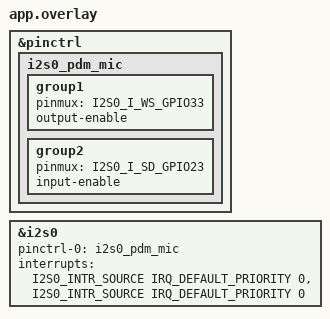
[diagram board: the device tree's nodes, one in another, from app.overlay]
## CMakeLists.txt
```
# Copyright (c) 2026 Eoin Jordan
# SPDX-License-Identifier: Apache-2.0
#
# "Hey Zephyr" wake word on the M5Stack ATOM Echo (ESP32-PICO-D4) under Zephyr.
# Same structure as the upstream zephyr/samples/hello-executorch sample: the
# model is embedded as a const array and only the operators it uses are linked.

cmake_minimum_required(VERSION 3.24)

set(CMAKE_SKIP_INSTALL_RULES ON CACHE BOOL "" FORCE)

set(ET_PTE_FILE_PATH
    "${CMAKE_CURRENT_SOURCE_DIR}/model/kws.pte"
    CACHE FILEPATH "Path to the ExecuTorch .pte model to embed"
)
if(NOT IS_ABSOLUTE "${ET_PTE_FILE_PATH}")
  get_filename_component(
    ET_PTE_FILE_PATH "${ET_PTE_FILE_PATH}" ABSOLUTE BASE_DIR
    "${CMAKE_CURRENT_SOURCE_DIR}"
  )
endif()
if(NOT EXISTS "${ET_PTE_FILE_PATH}")
  message(FATAL_ERROR "Model not found at ET_PTE_FILE_PATH=${ET_PTE_FILE_PATH}. "
                      "Run train/export_kws.py first or pass -DET_PTE_FILE_PATH=<file>.")
endif()

find_package(Zephyr REQUIRED HINTS $ENV{ZEPHYR_BASE})
project(atom_echo_hey_zephyr)

find_package(Python3 COMPONENTS Interpreter REQUIRED)

set(CMAKE_CXX_FLAGS
    "${CMAKE_CXX_FLAGS} -Wall -Wno-switch -Wno-float-conversion -ffunction-sections -fdata-sections"
)

if(NOT DEFINED EXECUTORCH_DIR)
  if(DEFINED ZEPHYR_EXECUTORCH_MODULE_DIR)
    set(EXECUTORCH_DIR ${ZEPHYR_EXECUTORCH_MODULE_DIR})
  else()
    message(FATAL_ERROR "ExecuTorch Zephyr module not found. Check west.yml and run west update.")
  endif()
endif()
message(STATUS "EXECUTORCH_DIR=${EXECUTORCH_DIR}")

include(${EXECUTORCH_DIR}/tools/cmake/Utils.cmake)
include(${EXECUTORCH_DIR}/backends/arm/cmake/ArmRunnerUtils.cmake)

if(NOT TARGET portable_kernels)
  set(EXECUTORCH_PORTABLE_BUILD_KERNELS_ONLY ON)
  add_subdirectory(
    ${EXECUTORCH_DIR}/kernels/portable
    ${CMAKE_CURRENT_BINARY_DIR}/executorch/kernels/portable
  )
  unset(EXECUTORCH_PORTABLE_BUILD_KERNELS_ONLY)
endif()

arm_runner_create_selected_ops_lib(
  LIB_NAME "kws_portable_ops_lib"
  FUNCTIONS_YAML "${EXECUTORCH_DIR}/kernels/portable/functions.yaml"
  OPS_FROM_MODEL "${ET_PTE_FILE_PATH}"
  KERNEL_LIBS portable_kernels
  DEPS executorch
  DTYPE_SELECTIVE_BUILD ""
)

set(_local_flatcc_root ${CMAKE_BINARY_DIR}/flatcc_src)
if(NOT EXISTS ${_local_flatcc_root}/CMakeLists.txt)
  file(MAKE_DIRECTORY ${_local_flatcc_root})
  execute_process(
    COMMAND ${CMAKE_COMMAND} -E copy_directory
            ${EXECUTORCH_DIR}/third-party/flatcc ${_local_flatcc_root}
  )
endif()
set(EXECUTORCH_FLATCC_SOURCE_ROOT ${_local_flatcc_root} CACHE PATH "" FORCE)
set(EXECUTORCH_FLATCC_INSTALL_ROOT ${_local_flatcc_root} CACHE PATH "" FORCE)

set(_model_pte_header ${CMAKE_CURRENT_BINARY_DIR}/model_pte.h)
add_custom_command(
  OUTPUT ${_model_pte_header}
  COMMAND ${Python3_EXECUTABLE} ${CMAKE_CURRENT_SOURCE_DIR}/scripts/pte_to_header.py
          --pte ${ET_PTE_FILE_PATH} --out ${_model_pte_header}
  DEPENDS ${ET_PTE_FILE_PATH} ${CMAKE_CURRENT_SOURCE_DIR}/scripts/pte_to_header.py
  COMMENT "Converting ${ET_PTE_FILE_PATH} to model_pte.h"
)
add_custom_target(gen_model_header DEPENDS ${_model_pte_header})
add_dependencies(app gen_model_header)

# The ExecuTorch module's runtime includes <zephyr/kernel.h>, which needs
# Zephyr's generated headers. Order it explicitly so a parallel build does not
# compile it before they exist.
if(TARGET zephyr_generated_headers)
  foreach(_t executorch_core executorch portable_kernels kernels_util_all_deps)
    if(TARGET ${_t})
      add_dependencies(${_t} zephyr_generated_headers)
    endif()
  endforeach()
endif()

target_sources(app PRIVATE src/main.cpp src/mic.c src/mfcc.c src/led.c)

target_compile_definitions(
  app PRIVATE
  APP_METHOD_ALLOCATOR_POOL_SIZE=${CONFIG_EXECUTORCH_METHOD_ALLOCATOR_POOL_SIZE}
  APP_TEMP_ALLOCATOR_POOL_SIZE=${CONFIG_EXECUTORCH_TEMP_ALLOCATOR_POOL_SIZE}
  MIC_RING_SAMPLES=16384
)

target_link_libraries(app PRIVATE libexecutorch kws_portable_ops_lib)
target_include_directories(app PRIVATE src ${CMAKE_CURRENT_BINARY_DIR})
```

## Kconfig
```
# Copyright (c) 2026 Eoin Jordan
# SPDX-License-Identifier: Apache-2.0

mainmenu "Hey Zephyr wake word on the M5Stack ATOM Echo"

config EXECUTORCH_METHOD_ALLOCATOR_POOL_SIZE
	int "ExecuTorch method allocator pool (bytes)"
	default 32768

config EXECUTORCH_TEMP_ALLOCATOR_POOL_SIZE
	int "ExecuTorch temp allocator pool (bytes)"
	default 8192

config APP_INFER_PERIOD_MS
	int "How often the newest second of audio is scored (ms)"
	default 250

config APP_WAKE_THRESHOLD_PERCENT
	int "p(hey_zephyr) that counts as a hit (percent)"
	default 85

config APP_WAKE_CONSECUTIVE
	int "Consecutive hits needed before a wake event"
	default 2

config APP_WAKE_HOLDOFF_MS
	int "Ignore further hits for this long after a wake event (ms)"
	default 1500

config APP_HEARTBEAT_MS
	int "Heartbeat JSON line period (ms)"
	default 5000

config APP_MIC_I2S_FRAME_HZ
	int "I2S frame clock the driver is configured for (Hz)"
	default 32000
	help
	  With 16-bit stereo frames the bit clock is 32 x this. 32000 gives the
	  1.024 MHz PDM clock that yields 16 kHz PCM from the ESP32's PDM-to-PCM
	  filter at DSR 8.

config APP_MIC_PICK
	int "Which halfword of each DMA word is the sample (-1 = measure and pick)"
	default -1
	range -1 2

choice APP_MIC_SLOT
	prompt "PDM slot the microphone drives"
	default APP_MIC_SLOT_RIGHT
	help
	  The SPM1423 on the ATOM Echo has its select pin tied so it answers in
	  the right slot (ESPHome and M5's own examples read the right channel).

config APP_MIC_SLOT_RIGHT
	bool "Right"

config APP_MIC_SLOT_LEFT
	bool "Left"

config APP_MIC_SLOT_BOTH
	bool "Both (stereo words, the louder half is picked)"

endchoice

config APP_MIC_DEBUG
	bool "Print microphone rates, RMS and peak frequency once a second"
	default n

source "Kconfig.zephyr"
```

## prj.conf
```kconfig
# Copyright (c) 2026 Eoin Jordan
# SPDX-License-Identifier: Apache-2.0

# ExecuTorch runtime, selective operator build
CONFIG_EXECUTORCH=y
CONFIG_EXECUTORCH_BUILD_PORTABLE_OPS=n
CONFIG_EXECUTORCH_ENABLE_LOGGING=y

CONFIG_CPP=y
CONFIG_STD_CPP17=y

CONFIG_MAIN_STACK_SIZE=12288
CONFIG_HEAP_MEM_POOL_SIZE=16384

# -O2: the portable kernels are generic loops; this is worth ~2x on the Xtensa
CONFIG_SPEED_OPTIMIZATIONS=y

CONFIG_REQUIRES_FLOAT_PRINTF=y
CONFIG_PRINTK=y

# Microphone over I2S0, SK6812 LED over SPI, button on GPIO39
CONFIG_I2S=y
CONFIG_I2S_ESP32_RX_BLOCK_COUNT=6
CONFIG_SPI=y
CONFIG_LED_STRIP=y
CONFIG_GPIO=y

# The ESP32-PICO-D4 in the ATOM Echo is a chip revision 1 part
CONFIG_ESP32_USE_UNSUPPORTED_REVISION=y

CONFIG_EXECUTORCH_METHOD_ALLOCATOR_POOL_SIZE=32768
CONFIG_EXECUTORCH_TEMP_ALLOCATOR_POOL_SIZE=8192
```

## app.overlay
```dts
/* Copyright (c) 2026 Eoin Jordan
 * SPDX-License-Identifier: Apache-2.0
 *
 * M5Stack ATOM Echo on top of the ATOM Lite board definition:
 *   SPM1423 PDM microphone  CLK GPIO33, DATA GPIO23  (I2S0, PDM RX)
 *   NS4168 I2S speaker      BCLK GPIO19, LRCK GPIO33, DATA GPIO22 (shares GPIO33; not used yet)
 *   SK6812 RGB LED          GPIO27 (board file: spi3 ws2812)
 *   button                  GPIO39 (board file: sw0)
 */

#include <zephyr/dt-bindings/pinctrl/esp32-pinctrl.h>

&pinctrl {
	i2s0_pdm_mic: i2s0_pdm_mic {
		group1 {
			pinmux = <I2S0_I_WS_GPIO33>;
			output-enable;
		};
		group2 {
			pinmux = <I2S0_I_SD_GPIO23>;
			input-enable;
		};
	};
};

&i2s0 {
	status = "okay";
	pinctrl-0 = <&i2s0_pdm_mic>;
	pinctrl-names = "default";
	interrupts = <I2S0_INTR_SOURCE IRQ_DEFAULT_PRIORITY 0>,
		     <I2S0_INTR_SOURCE IRQ_DEFAULT_PRIORITY 0>;
	interrupt-names = "rx", "tx";
};
```

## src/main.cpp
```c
/* Copyright (c) 2026 Eoin Jordan
 * SPDX-License-Identifier: Apache-2.0
 *
 * "Hey Zephyr" on the M5Stack ATOM Echo: Zephyr + ExecuTorch wake-word spotter.
 *
 *   SPM1423 PDM mic --I2S0--> 16 kHz ring --MFCC 49x10--> ExecuTorch KwsNet --> p(wake)
 *                                                                |
 *                        SK6812 LED (blue listening, green wake) <+--> JSON lines on UART0
 *                                                                     (linux/ha_bridge.py -> Home Assistant)
 *
 * Boot self-tests, no human needed:
 *   1. the C MFCC of an embedded clip against the Python MFCC of the same clip
 *   2. the model on those features against the PyTorch logits
 * Then the live loop: every APP_INFER_PERIOD_MS take the newest second of
 * audio, run the net, and fire a wake event after APP_WAKE_CONSECUTIVE
 * windows above APP_WAKE_THRESHOLD_PERCENT.
 */

#include <executorch/extension/data_loader/buffer_data_loader.h>
#include <executorch/runtime/core/memory_allocator.h>
#include <executorch/runtime/core/span.h>
#include <executorch/runtime/executor/memory_manager.h>
#include <executorch/runtime/executor/method.h>
#include <executorch/runtime/executor/program.h>
#include <executorch/runtime/platform/log.h>
#include <executorch/runtime/platform/runtime.h>

#include <zephyr/drivers/gpio.h>
#include <zephyr/kernel.h>
#include <zephyr/sys/printk.h>
#include <zephyr/version.h>

#include <cmath>
#include <cstdint>
#include <cstring>
#include <vector>

#include "features_test.h"
#include "kws_test_input.h"
#include "led.h"
#include "mfcc.h"
#include "mic.h"
#include "model_pte.h"

using executorch::aten::Tensor;
using executorch::aten::TensorImpl;
using executorch::extension::BufferDataLoader;
using executorch::runtime::Error;
using executorch::runtime::EValue;
using executorch::runtime::HierarchicalAllocator;
using executorch::runtime::MemoryAllocator;
using executorch::runtime::MemoryManager;
using executorch::runtime::Method;
using executorch::runtime::MethodMeta;
using executorch::runtime::Program;
using executorch::runtime::Result;
using executorch::runtime::Span;
using executorch::runtime::TensorInfo;

static_assert(KWS_FRAMES == MFCC_FRAMES && KWS_COEFFS == MFCC_N_COEF, "feature shape mismatch");
static_assert(FEAT_TEST_SAMPLES >= MFCC_WINDOW_SAMPLES, "test clip too short");

#ifndef APP_METHOD_ALLOCATOR_POOL_SIZE
#define APP_METHOD_ALLOCATOR_POOL_SIZE (48 * 1024)
#endif
#ifndef APP_TEMP_ALLOCATOR_POOL_SIZE
#define APP_TEMP_ALLOCATOR_POOL_SIZE (8 * 1024)
#endif

alignas(16) static uint8_t method_pool[APP_METHOD_ALLOCATOR_POOL_SIZE];
alignas(16) static uint8_t temp_pool[APP_TEMP_ALLOCATOR_POOL_SIZE];

static const struct gpio_dt_spec button = GPIO_DT_SPEC_GET_OR(DT_ALIAS(sw0), gpios, {0});

namespace {

struct Runner {
	BufferDataLoader loader{model_pte, model_pte_len};
	MemoryAllocator method_allocator{APP_METHOD_ALLOCATOR_POOL_SIZE, method_pool};
	MemoryAllocator temp_allocator{APP_TEMP_ALLOCATOR_POOL_SIZE, temp_pool};
	std::vector<Span<uint8_t>> planned_spans;
	Program *program = nullptr;
	Method *method = nullptr;
	float *input = nullptr;
	size_t input_numel = 0;
	Tensor *input_tensor = nullptr;

	Error init();
	Error run(const float *features, float *logits, uint32_t *us);
};

Error Runner::init()
{
	Result<Program> program_res = Program::load(&loader);
	if (!program_res.ok()) {
		ET_LOG(Error, "Program::load failed: 0x%x", (unsigned)program_res.error());
		return program_res.error();
	}
	program = new Program(std::move(program_res.get()));

	const char *method_name = program->get_method_name(0).get();
	Result<MethodMeta> meta = program->method_meta(method_name);
	if (!meta.ok()) {
		return meta.error();
	}
	for (size_t id = 0; id < meta->num_memory_planned_buffers(); ++id) {
		size_t size = static_cast<size_t>(meta->memory_planned_buffer_size(id).get());
		uint8_t *buf = static_cast<uint8_t *>(method_allocator.allocate(size, 16));
		if (buf == nullptr) {
			ET_LOG(Error, "planned buffer %zu (%zu B) does not fit the method pool", id, size);
			return Error::MemoryAllocationFailed;
		}
		printk("planned buffer %u: %u bytes\n", (unsigned)id, (unsigned)size);
		planned_spans.push_back({buf, size});
	}
	static HierarchicalAllocator planned_memory({planned_spans.data(), planned_spans.size()});
	static MemoryManager memory_manager(&method_allocator, &planned_memory, &temp_allocator);

	Result<Method> method_res = program->load_method(method_name, &memory_manager);
	if (!method_res.ok()) {
		ET_LOG(Error, "load_method(%s) failed: 0x%x", method_name, (unsigned)method_res.error());
		return method_res.error();
	}
	method = new Method(std::move(method_res.get()));

	Result<TensorInfo> in_meta = meta->input_tensor_meta(0);
	if (!in_meta.ok()) {
		return in_meta.error();
	}
	input_numel = in_meta->nbytes() / sizeof(float);
	input = static_cast<float *>(method_allocator.allocate(in_meta->nbytes(), 16));
	if (input == nullptr) {
		return Error::MemoryAllocationFailed;
	}
	static TensorImpl impl(
		in_meta->scalar_type(), in_meta->sizes().size(),
		const_cast<TensorImpl::SizesType *>(in_meta->sizes().data()), input,
		const_cast<TensorImpl::DimOrderType *>(in_meta->dim_order().data()));
	static Tensor tensor(&impl);
	input_tensor = &tensor;

	printk("method '%s' loaded; input numel %u; pool used %u / %u bytes\n", method_name,
	       (unsigned)input_numel, (unsigned)method_allocator.used_size(),
	       (unsigned)method_allocator.size());
	return Error::Ok;
}

Error Runner::run(const float *features, float *logits, uint32_t *us)
{
	std::memcpy(input, features, input_numel * sizeof(float));
	Error err = method->set_input(EValue(*input_tensor), 0);
	if (err != Error::Ok) {
		return err;
	}
	uint32_t t0 = k_cycle_get_32();
	err = method->execute();
	uint32_t t1 = k_cycle_get_32();
	if (err != Error::Ok) {
		return err;
	}
	*us = k_cyc_to_us_floor32(t1 - t0);
	const EValue &out = method->get_output(0);
	if (!out.isTensor()) {
		return Error::InvalidState;
	}
	const float *data = out.toTensor().const_data_ptr<float>();
	for (size_t i = 0; i < KWS_LABELS; ++i) {
		logits[i] = data[i];
	}
	return Error::Ok;
}

static float features[KWS_FRAMES * KWS_COEFFS];
static int16_t window[MFCC_WINDOW_SAMPLES];

void normalise(float *f)
{
	for (int t = 0; t < KWS_FRAMES; t++) {
		for (int c = 0; c < KWS_COEFFS; c++) {
			f[t * KWS_COEFFS + c] = (f[t * KWS_COEFFS + c] - kFeatMean[c]) / kFeatStd[c];
		}
	}
}

void softmax(const float *logits, float *p)
{
	float m = logits[0];
	for (int i = 1; i < KWS_LABELS; i++) {
		m = fmaxf(m, logits[i]);
	}
	float s = 0.f;
	for (int i = 0; i < KWS_LABELS; i++) {
		p[i] = expf(logits[i] - m);
		s += p[i];
	}
	for (int i = 0; i < KWS_LABELS; i++) {
		p[i] /= s;
	}
}

bool self_test(Runner &runner)
{
	/* 1. front end */
	uint32_t t0 = k_cycle_get_32();
	mfcc_compute(kTestAudio, features);
	uint32_t mfcc_us = k_cyc_to_us_floor32(k_cycle_get_32() - t0);
	float fdiff = 0.f;
	for (int i = 0; i < KWS_FRAMES * KWS_COEFFS; i++) {
		fdiff = fmaxf(fdiff, fabsf(features[i] - kTestMfcc[i]));
	}
	bool feat_ok = fdiff < 2e-2f;
	printk("  mfcc : 49 frames in %u us, max|c-python|=%.2e %s\n", mfcc_us, (double)fdiff,
	       feat_ok ? "ok" : "MISMATCH");

	/* 2. model on the Python-normalised features (the exact test input) */
	float logits[KWS_LABELS], p[KWS_LABELS];
	uint32_t us = 0;
	if (runner.run(kTestInput, logits, &us) != Error::Ok) {
		printk("  kws  : inference failed\n");
		return false;
	}
	float ldiff = 0.f;
	int pred = 0;
	printk("  kws  : logits [");
	for (int i = 0; i < KWS_LABELS; i++) {
		printk("%s%.4f", i ? " " : "", (double)logits[i]);
		ldiff = fmaxf(ldiff, fabsf(logits[i] - kTestLogits[i]));
		if (logits[i] > logits[pred]) {
			pred = i;
		}
	}
	softmax(logits, p);
	printk("] pred=%d (%s) expected=%d max|esp32-pytorch|=%.1e (%u us)\n", pred, kKwsLabels[pred],
	       KWS_TEST_ARGMAX, (double)ldiff, us);
	bool model_ok = pred == KWS_TEST_ARGMAX && ldiff < 1e-3f;

	/* 3. the whole chain: C features, normalised here, through the model */
	normalise(features);
	if (runner.run(features, logits, &us) == Error::Ok) {
		float cdiff = 0.f;
		for (int i = 0; i < KWS_LABELS; i++) {
			cdiff = fmaxf(cdiff, fabsf(logits[i] - kTestLogits[i]));
		}
		printk("  chain: C mfcc -> model, max|logit diff|=%.1e\n", (double)cdiff);
	}
	return feat_ok && model_ok;
}

} // namespace

int main(void)
{
	executorch::runtime::runtime_init();
	mfcc_init();
	led_init();

	printk("\nHey Zephyr on %s (Zephyr %s): ExecuTorch wake word\n", CONFIG_BOARD_TARGET,
	       KERNEL_VERSION_STRING);
	printk("model: %u bytes in flash, method pool %u B, temp pool %u B\n",
	       (unsigned)model_pte_len, (unsigned)APP_METHOD_ALLOCATOR_POOL_SIZE,
	       (unsigned)APP_TEMP_ALLOCATOR_POOL_SIZE);

	static Runner runner;
	if (runner.init() != Error::Ok) {
		printk("FAIL: runtime init\n");
		led_set(LED_ERROR);
		return 1;
	}

	printk("\nself-test:\n");
	bool ok = self_test(runner);
	printk(ok ? "SELF-TEST PASS\n" : "SELF-TEST FAIL\n");
	led_set(ok ? LED_LISTENING : LED_ERROR);

	bool have_button = button.port != nullptr && gpio_is_ready_dt(&button) &&
			   gpio_pin_configure_dt(&button, GPIO_INPUT) == 0;

	if (mic_init() != 0) {
		printk("mic: init failed; staying in self-test mode\n");
		led_set(LED_ERROR);
		for (;;) {
			k_msleep(1000);
		}
	}

	uint32_t seq = 0, above = 0;
	int64_t last_wake = -100000, last_beat = 0, last_stats = 0;
	bool muted = false, btn_was = false;
	float logits[KWS_LABELS], p[KWS_LABELS];

	for (;;) {
		k_msleep(CONFIG_APP_INFER_PERIOD_MS);
		int64_t now = k_uptime_get();

		if (have_button) {
			bool btn = gpio_pin_get_dt(&button) > 0;
			if (btn && !btn_was) {
				muted = !muted;
				led_set(muted ? LED_MUTED : LED_LISTENING);
				printk("{\"seq\":%u,\"t_ms\":%lld,\"muted\":%d}\n", seq++, (long long)now, muted);
			}
			btn_was = btn;
		}

#ifdef CONFIG_APP_MIC_DEBUG
		if (now - last_stats >= 1000) {
			struct mic_stats st;
			mic_get_stats(&st);
			static float power[MFCC_NFFT / 2 + 1];
			int peak = 2;
			if (mic_read_latest(window, MFCC_FRAME_LEN) == MFCC_FRAME_LEN) {
				mfcc_set_dc(window, MFCC_FRAME_LEN);
				mfcc_power_spectrum(window, power);
				for (int k = 2; k < MFCC_NFFT / 2; k++) {
					if (power[k] > power[peak]) {
						peak = k;
					}
				}
			}
			printk("mic: %u words/s %u samples/s pick %d rms lo %.0f hi %.0f peak %d Hz overruns %u\n",
			       st.words_per_s, st.samples_per_s, st.pick, (double)st.rms_lo,
			       (double)st.rms_hi, peak * MFCC_SAMPLE_RATE / MFCC_NFFT, st.overruns);
			if ((now / 1000) % 5 == 0) {
				printk("mic: raw:");
				for (int i = 0; i < 32; i++) {
					printk(" %d", window[i]);
				}
				printk("\n");
			}
			last_stats = now;
		}
#endif

		if (muted || mic_sample_count() < MFCC_WINDOW_SAMPLES) {
			continue;
		}
		if (mic_read_latest(window, MFCC_WINDOW_SAMPLES) != MFCC_WINDOW_SAMPLES) {
			continue;
		}
		mfcc_compute(window, features);
		normalise(features);
		uint32_t us = 0;
		if (runner.run(features, logits, &us) != Error::Ok) {
			printk("kws: inference failed\n");
			continue;
		}
		softmax(logits, p);
		float pw = p[KWS_WAKE_INDEX];
		int pred = 0;
		for (int i = 1; i < KWS_LABELS; i++) {
			if (p[i] > p[pred]) {
				pred = i;
			}
		}

		if (pw * 100.f >= CONFIG_APP_WAKE_THRESHOLD_PERCENT) {
			above++;
		} else {
			above = 0;
		}
		bool holdoff = now - last_wake < CONFIG_APP_WAKE_HOLDOFF_MS;
		if (above >= CONFIG_APP_WAKE_CONSECUTIVE && !holdoff) {
			last_wake = now;
			above = 0;
			led_set(LED_WAKE);
			printk("{\"seq\":%u,\"t_ms\":%lld,\"wake\":1,\"label\":\"%s\",\"p\":%.3f,\"infer_us\":%u}\n",
			       seq++, (long long)now, kKwsLabels[KWS_WAKE_INDEX], (double)pw, us);
		} else if (now - last_wake >= 1000 && now - last_wake < 1000 + CONFIG_APP_INFER_PERIOD_MS) {
			led_set(LED_LISTENING);
		}

		if (now - last_beat >= CONFIG_APP_HEARTBEAT_MS) {
			last_beat = now;
			printk("{\"seq\":%u,\"t_ms\":%lld,\"wake\":0,\"top\":\"%s\",\"p_wake\":%.3f,\"infer_us\":%u,\"samples\":%u}\n",
			       seq++, (long long)now, kKwsLabels[pred], (double)pw, us,
			       (unsigned)mic_sample_count());
		}
	}
	return 0;
}
```

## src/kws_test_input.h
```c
/* Generated by train/export_kws.py; do not edit. */
#pragma once
#define KWS_FRAMES 49
#define KWS_COEFFS 10
#define KWS_LABELS 3
#define KWS_WAKE_INDEX 2
static const char *const kKwsLabels[KWS_LABELS] = {"_silence_", "_unknown_", "hey_zephyr"};
static const float kTestInput[490] = {
	0.710475f, 0.383596f, 1.031747f, 0.640857f, -0.883264f, -1.766535f, -2.264280f, -3.613621f, -3.086460f, -2.402045f,
	0.680841f, 0.023912f, 0.738081f, -0.225834f, -1.656382f, -3.315896f, -3.276140f, -2.667520f, -1.095832f, 0.442188f,
	0.631626f, 0.010638f, 0.779248f, -0.660919f, -2.172182f, -3.212636f, -1.778455f, -0.930555f, 1.187042f, 4.020188f,
	0.648124f, 0.081330f, 0.022163f, -1.820403f, -1.809350f, -2.338983f, -0.315286f, 2.406794f, 3.151443f, 3.617784f,
	0.579187f, -0.444523f, -0.486469f, -2.397441f, -2.218276f, -1.360894f, 1.315567f, 3.153624f, 3.262369f, 0.643913f,
	0.593069f, -0.274290f, -0.313599f, -2.485307f, -1.814779f, -0.403226f, 2.070472f, 3.551968f, 1.505668f, -2.421746f,
	0.623205f, -0.609376f, -0.713128f, -1.851889f, -0.659541f, 1.172763f, 3.751838f, 2.877345f, -0.954952f, -3.441116f,
	0.614598f, -0.673720f, -1.373932f, -1.848752f, -0.104117f, 2.346666f, 2.723653f, -0.001940f, -3.227724f, -2.704073f,
	0.633264f, -0.724207f, -1.437577f, -2.364023f, 0.070539f, 2.308997f, 1.169751f, -1.903437f, -2.988611f, -1.230747f,
	0.530588f, -0.894958f, -1.319849f, -1.846206f, 1.681835f, 4.066416f, 1.038055f, -2.161721f, -2.302732f, 0.210446f,
	0.543188f, -0.958238f, -1.519286f, -1.798930f, 1.213413f, 2.484611f, -0.761060f, -2.946366f, -0.699265f, 2.744888f,
	0.545192f, -1.133469f, -1.612826f, -1.407369f, 1.742016f, 2.224671f, -0.583432f, -1.936020f, 1.855694f, 4.607385f,
	0.561746f, -0.959734f, -1.193500f, -1.085330f, 1.813917f, 2.079829f, -2.221151f, -1.822354f, 2.412246f, 1.640756f,
	0.556835f, -1.376304f, -1.781021f, -0.379303f, 1.715137f, 0.347333f, -2.144161f, 0.111992f, 2.468451f, 0.381802f,
	0.483453f, -1.169942f, -1.512539f, 0.326625f, 2.275242f, -0.313918f, -2.296731f, 0.668300f, 2.883527f, -1.626794f,
	0.567963f, -1.164145f, -1.569798f, 0.257223f, 1.746330f, -1.209097f, -2.083626f, 1.609024f, 2.299941f, -2.539796f,
	0.556182f, -1.236422f, -1.404445f, 0.928538f, 1.857870f, -1.470565f, -1.486142f, 2.345239f, 1.211654f, -2.943000f,
	0.924202f, -0.502781f, -2.688861f, -0.469162f, 2.203130f, -0.576806f, -1.577902f, 0.362773f, 1.086187f, -0.083173f,
	0.741256f, -1.236255f, -2.218025f, 0.543634f, 2.335791f, -0.878943f, -1.926195f, 0.409526f, -1.028832f, 0.826156f,
	0.655562f, -1.119632f, -1.985927f, 1.668630f, 2.363337f, -0.928944f, -0.638089f, -0.117745f, -0.681345f, 2.060840f,
	0.700964f, -1.231870f, -1.994379f, 0.873215f, 1.433679f, -1.579463f, -0.624163f, -0.597316f, -1.066293f, 3.026206f,
	0.701212f, -1.401820f, -1.928386f, 1.052890f, 1.421258f, -0.179713f, 0.328010f, -0.883608f, -1.745821f, 3.676780f,
	0.630057f, -1.791934f, -2.247543f, 0.531182f, 0.960362f, -0.092546f, 0.514247f, -1.631165f, -1.127879f, 5.313008f,
	0.682858f, -1.407079f, -1.681477f, 0.998628f, 0.748957f, -0.042711f, 0.280640f, -3.637921f, -0.791914f, 5.781610f,
	0.676696f, -1.254496f, -1.549123f, 1.148335f, 0.839728f, 0.665763f, 0.862142f, -3.411474f, 1.082144f, 5.206754f,
	0.639176f, -1.446599f, -1.902727f, 0.738524f, 0.191762f, 0.827312f, 0.778103f, -3.482848f, 2.899383f, 5.588547f,
	0.652810f, -1.615802f, -1.453214f, 0.758446f, 0.490461f, 1.877227f, 0.092995f, -4.233899f, 2.651208f, 3.377489f,
	0.652296f, -1.386571f, -1.185934f, 0.523110f, 0.134165f, 2.366330f, -0.562256f, -4.543561f, 2.864267f, 3.478714f,
	0.644712f, -1.547253f, -1.540110f, 0.636550f, 0.153058f, 2.160360f, -0.360790f, -3.659353f, 3.319145f, 1.368916f,
	0.617244f, -1.688100f, -1.257816f, 0.467137f, -0.091951f, 3.411831f, -1.763266f, -4.235921f, 3.767978f, 1.756774f,
	0.665846f, -1.549456f, -1.053556f, 0.029649f, 0.093214f, 3.538093f, -1.110420f, -3.112827f, 3.248299f, 1.182002f,
	0.639973f, -1.513441f, -1.129886f, 0.419587f, -0.113053f, 3.135770f, -1.836284f, -2.744657f, 4.201185f, 0.904690f,
	0.852862f, -1.004520f, -1.338308f, -0.305194f, -0.163242f, 2.790686f, -1.558161f, -1.193223f, 2.835664f, -0.857320f,
	0.511888f, -1.570578f, 0.464544f, 0.862133f, -0.550582f, 1.791636f, -2.142209f, 0.492877f, 2.378541f, -2.117406f,
	0.520252f, -1.570299f, 0.345095f, -0.005870f, -1.241920f, 1.420182f, -1.987312f, 0.388157f, -0.529839f, -2.085799f,
	0.501849f, -1.714938f, 0.482172f, -0.114814f, -0.713981f, 2.941787f, -1.819195f, 1.830235f, 0.373003f, -0.464234f,
	0.482038f, -1.711087f, 0.590068f, 0.342203f, -0.868306f, 1.637547f, -1.404537f, 1.561505f, -0.804600f, -0.671201f,
	0.542792f, -1.669556f, 0.596013f, 0.174154f, -0.817298f, 1.397758f, -1.862096f, 1.756171f, -1.155335f, -0.105688f,
	0.566971f, -1.713335f, 0.346501f, -0.042591f, -0.072029f, 1.795937f, -1.605573f, 2.054151f, -1.702398f, 0.658015f,
	0.497521f, -1.783907f, 0.246067f, -0.932413f, -0.104161f, 1.561972f, -0.978754f, 3.424969f, -0.777585f, 2.194805f,
	0.487347f, -1.813841f, 0.622773f, -0.715625f, -0.346783f, 0.552699f, -2.026786f, 2.034561f, -2.830204f, 1.547716f,
	0.444352f, -2.208828f, -0.087107f, -0.400144f, 0.218353f, 1.521516f, -1.434662f, 1.914636f, -1.275749f, 2.632122f,
	0.458015f, -1.963343f, 0.657668f, -1.037077f, -0.183007f, -0.107193f, -1.248922f, 1.748958f, -1.942432f, 2.948104f,
	0.526646f, -1.630674f, 0.752461f, -0.772284f, -0.276293f, -0.549396f, -1.059728f, 1.632423f, -1.621404f, 2.793757f,
	0.572635f, -1.448961f, 0.889059f, -0.693104f, 0.891519f, -0.241548f, -0.220592f, 1.328698f, -1.346135f, 2.547741f,
	0.507082f, -1.768877f, 0.549012f, -1.632542f, 0.840886f, -0.438393f, -0.657989f, 1.015801f, -0.973776f, 1.950694f,
	0.451339f, -1.913547f, 0.808770f, -0.784830f, 0.652259f, -1.279162f, 0.185931f, 0.206644f, -0.071048f, 2.048476f,
	0.529362f, -1.937673f, 0.759016f, -0.772977f, 1.163457f, -0.533523f, 0.186642f, -0.826074f, -0.240446f, 1.543778f,
	0.490499f, -1.923544f, 0.858483f, -0.728427f, 1.478029f, -0.830113f, 0.628667f, 0.251185f, 1.066585f, 0.853097f,
};
static const float kTestLogits[KWS_LABELS] = {-32.972908f, 11.314022f, -9.824173f};
#define KWS_TEST_ARGMAX 1
```

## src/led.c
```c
/* Copyright (c) 2026 Eoin Jordan
 * SPDX-License-Identifier: Apache-2.0
 *
 * The ATOM's single SK6812 on GPIO27, through Zephyr's ws2812-spi led_strip
 * driver that the m5stack_atom_lite board already defines.
 */

#include "led.h"

#include <zephyr/device.h>
#include <zephyr/drivers/led_strip.h>
#include <zephyr/kernel.h>
#include <zephyr/sys/printk.h>

static const struct device *const strip = DEVICE_DT_GET(DT_ALIAS(led_strip));

int led_init(void)
{
	if (!device_is_ready(strip)) {
		printk("led: strip not ready\n");
		return -ENODEV;
	}
	led_set(LED_OFF);
	return 0;
}

void led_set(enum led_state s)
{
	struct led_rgb px = {0};

	switch (s) {
	case LED_LISTENING:
		px.b = 24;
		break;
	case LED_WAKE:
		px.g = 160;
		break;
	case LED_MUTED:
		px.r = 20;
		px.b = 20;
		break;
	case LED_ERROR:
		px.r = 120;
		break;
	default:
		break;
	}
	if (device_is_ready(strip)) {
		led_strip_update_rgb(strip, &px, 1);
	}
}
```

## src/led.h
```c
/* Copyright (c) 2026 Eoin Jordan
 * SPDX-License-Identifier: Apache-2.0
 */
#pragma once

#ifdef __cplusplus
extern "C" {
#endif

enum led_state {
	LED_OFF,
	LED_LISTENING, /* dim blue */
	LED_WAKE,      /* green */
	LED_MUTED,     /* dim purple */
	LED_ERROR,     /* red */
};

int led_init(void);
void led_set(enum led_state s);

#ifdef __cplusplus
}
#endif
```

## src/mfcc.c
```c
/* Copyright (c) 2026 Eoin Jordan
 * SPDX-License-Identifier: Apache-2.0
 *
 * MFCC in plain C float: periodic Hann window, 512-point radix-2 complex FFT
 * (real input in the real part, so bins 0..256 are the spectrum), 40 mel
 * triangles built from bin centre frequencies, natural log, orthonormal DCT-II.
 * The same recipe as train/features.py; the device checks the two agree at boot.
 */

#include "mfcc.h"

#include <math.h>
#include <string.h>

#define NBINS (MFCC_NFFT / 2 + 1)
#define PI_F  3.14159265358979f

static float win[MFCC_FRAME_LEN];
static float twr[MFCC_NFFT / 2], twi[MFCC_NFFT / 2];
static uint16_t bitrev[MFCC_NFFT];
/* Each mel filter is non-zero on a contiguous bin range: store start, count, weights. */
static uint16_t mel_start[MFCC_N_MEL], mel_count[MFCC_N_MEL];
static float mel_w[MFCC_N_MEL][24];
static float dct[MFCC_N_COEF][MFCC_N_MEL];

static float re[MFCC_NFFT], im[MFCC_NFFT];

static float hz_to_mel(float f)
{
	return 2595.0f * log10f(1.0f + f / 700.0f);
}

static float mel_to_hz(float m)
{
	return 700.0f * (powf(10.0f, m / 2595.0f) - 1.0f);
}

void mfcc_init(void)
{
	for (int n = 0; n < MFCC_FRAME_LEN; n++) {
		win[n] = 0.5f - 0.5f * cosf(2.0f * PI_F * (float)n / (float)MFCC_FRAME_LEN);
	}
	for (int k = 0; k < MFCC_NFFT / 2; k++) {
		twr[k] = cosf(-2.0f * PI_F * (float)k / (float)MFCC_NFFT);
		twi[k] = sinf(-2.0f * PI_F * (float)k / (float)MFCC_NFFT);
	}
	for (int i = 0; i < MFCC_NFFT; i++) {
		unsigned r = 0, v = (unsigned)i;
		for (int b = 0; b < 9; b++) { /* log2(512) */
			r = (r << 1) | (v & 1u);
			v >>= 1;
		}
		bitrev[i] = (uint16_t)r;
	}

	float edges[MFCC_N_MEL + 2];
	float mlo = hz_to_mel(20.0f), mhi = hz_to_mel(4000.0f);
	for (int m = 0; m < MFCC_N_MEL + 2; m++) {
		edges[m] = mel_to_hz(mlo + (mhi - mlo) * (float)m / (float)(MFCC_N_MEL + 1));
	}
	for (int m = 0; m < MFCC_N_MEL; m++) {
		float lo = edges[m], c = edges[m + 1], hi = edges[m + 2];
		int first = -1, count = 0;
		for (int k = 0; k < NBINS; k++) {
			float f = (float)k * ((float)MFCC_SAMPLE_RATE / (float)MFCC_NFFT);
			float up = (f - lo) / (c - lo);
			float down = (hi - f) / (hi - c);
			float w = up < down ? up : down;
			if (w > 1.0f) {
				w = 1.0f;
			}
			if (w > 0.0f) {
				if (first < 0) {
					first = k;
				}
				if (count < 24) {
					mel_w[m][count++] = w;
				}
			} else if (first >= 0) {
				break;
			}
		}
		mel_start[m] = (uint16_t)(first < 0 ? 0 : first);
		mel_count[m] = (uint16_t)count;
	}

	for (int i = 0; i < MFCC_N_COEF; i++) {
		float scale = sqrtf(2.0f / (float)MFCC_N_MEL) * (i == 0 ? 1.0f / sqrtf(2.0f) : 1.0f);
		for (int j = 0; j < MFCC_N_MEL; j++) {
			dct[i][j] = scale * cosf(PI_F / (float)MFCC_N_MEL * ((float)j + 0.5f) * (float)i);
		}
	}
}

static void fft512(void)
{
	for (int i = 0; i < MFCC_NFFT; i++) {
		int j = bitrev[i];
		if (j > i) {
			float t = re[i];
			re[i] = re[j];
			re[j] = t;
			t = im[i];
			im[i] = im[j];
			im[j] = t;
		}
	}
	for (int len = 2; len <= MFCC_NFFT; len <<= 1) {
		int half = len >> 1;
		int step = MFCC_NFFT / len;
		for (int i = 0; i < MFCC_NFFT; i += len) {
			for (int k = 0; k < half; k++) {
				float wr = twr[k * step], wi = twi[k * step];
				int a = i + k, b = i + k + half;
				float xr = re[b] * wr - im[b] * wi;
				float xi = re[b] * wi + im[b] * wr;
				re[b] = re[a] - xr;
				im[b] = im[a] - xi;
				re[a] += xr;
				im[a] += xi;
			}
		}
	}
}

static float dc_offset;

void mfcc_set_dc(const int16_t *audio, size_t n)
{
	int64_t acc = 0;
	for (size_t i = 0; i < n; i++) {
		acc += audio[i];
	}
	dc_offset = n ? (float)acc / (float)n : 0.0f;
}

void mfcc_power_spectrum(const int16_t *audio, float *out)
{
	for (int n = 0; n < MFCC_FRAME_LEN; n++) {
		re[n] = ((float)audio[n] - dc_offset) * (1.0f / 32768.0f) * win[n];
		im[n] = 0.0f;
	}
	memset(&re[MFCC_FRAME_LEN], 0, sizeof(float) * (MFCC_NFFT - MFCC_FRAME_LEN));
	memset(&im[MFCC_FRAME_LEN], 0, sizeof(float) * (MFCC_NFFT - MFCC_FRAME_LEN));
	fft512();
	for (int k = 0; k < NBINS; k++) {
		out[k] = re[k] * re[k] + im[k] * im[k];
	}
}

void mfcc_compute(const int16_t *audio, float *out)
{
	static float power[NBINS];
	static float logmel[MFCC_N_MEL];

	mfcc_set_dc(audio, MFCC_WINDOW_SAMPLES);
	for (int t = 0; t < MFCC_FRAMES; t++) {
		mfcc_power_spectrum(&audio[t * MFCC_HOP], power);
		for (int m = 0; m < MFCC_N_MEL; m++) {
			float e = 0.0f;
			const float *w = mel_w[m];
			const float *p = &power[mel_start[m]];
			for (int k = 0; k < mel_count[m]; k++) {
				e += w[k] * p[k];
			}
			logmel[m] = logf(e + 1e-6f);
		}
		float *o = &out[t * MFCC_N_COEF];
		for (int i = 0; i < MFCC_N_COEF; i++) {
			float c = 0.0f;
			for (int j = 0; j < MFCC_N_MEL; j++) {
				c += dct[i][j] * logmel[j];
			}
			o[i] = c;
		}
	}
}
```

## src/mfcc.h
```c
/* Copyright (c) 2026 Eoin Jordan
 * SPDX-License-Identifier: Apache-2.0
 *
 * MFCC front end matching train/features.py. See that file for the numbers.
 */
#pragma once

#include <stddef.h>
#include <stdint.h>

#ifdef __cplusplus
extern "C" {
#endif

#define MFCC_SAMPLE_RATE 16000
#define MFCC_FRAME_LEN   480
#define MFCC_HOP         320
#define MFCC_NFFT        512
#define MFCC_N_MEL       40
#define MFCC_N_COEF      10
#define MFCC_FRAMES      49
#define MFCC_WINDOW_SAMPLES (MFCC_HOP * (MFCC_FRAMES - 1) + MFCC_FRAME_LEN)

/* Build the window, twiddles, mel filterbank and DCT tables. Call once. */
void mfcc_init(void);

/* audio: at least MFCC_WINDOW_SAMPLES int16 samples.
 * out: MFCC_FRAMES * MFCC_N_COEF floats, frame-major. */
void mfcc_compute(const int16_t *audio, float *out);

/* The window mean that mfcc_power_spectrum() subtracts (PDM mics have a DC offset);
 * mfcc_compute() sets it from the whole window. */
void mfcc_set_dc(const int16_t *audio, size_t n);

/* Power spectrum of one frame starting at audio[0]; out: MFCC_NFFT/2 + 1 floats.
 * Exposed for the microphone debug mode (peak-frequency readout). */
void mfcc_power_spectrum(const int16_t *audio, float *out);

#ifdef __cplusplus
}
#endif
```

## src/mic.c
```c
/* Copyright (c) 2026 Eoin Jordan
 * SPDX-License-Identifier: Apache-2.0
 *
 * PDM microphone capture on the ESP32 (hardware v1 I2S) under Zephyr.
 *
 * Zephyr's I2S driver has no PDM mode, so the trick is: configure it as a
 * standard 16-bit stereo master at 32 kHz, which puts the bit clock at
 * 32000 x 32 = 1.024 MHz, exactly the 64 x 16 kHz PDM clock the SPM1423
 * wants, then flip I2S0 into PDM-to-PCM receive mode with the ESP-IDF HAL
 * before starting it. The clock comes out on the RX word-select pin (GPIO33)
 * and the PDM data goes in on GPIO23; that is how ESP-IDF wires PDM RX too.
 *
 * What lands in the DMA buffers depends on the silicon's mono packing, so the
 * first half second is spent measuring the word rate and picking the halfword
 * stream that gives 16 kHz. The choice and the rates are printed; the
 * APP_MIC_PICK Kconfig option can pin it.
 */

#include "mic.h"

#include <zephyr/device.h>
#include <zephyr/drivers/i2s.h>
#include <zephyr/kernel.h>
#include <zephyr/sys/printk.h>

#include <hal/i2s_ll.h>
#include <soc/i2s_struct.h>

#include <math.h>
#include <string.h>

#define I2S_NODE DT_NODELABEL(i2s0)

#define FRAME_HZ    CONFIG_APP_MIC_I2S_FRAME_HZ /* 32000: bck = 1.024 MHz */
#define BLOCK_WORDS 512                         /* 32-bit words per DMA block */
#define BLOCK_BYTES (BLOCK_WORDS * 4)
#define BLOCK_COUNT 6
#define RING_SAMPLES (MIC_RING_SAMPLES)

K_MEM_SLAB_DEFINE_STATIC(mic_slab, BLOCK_BYTES, BLOCK_COUNT, 4);

static const struct device *const i2s = DEVICE_DT_GET(I2S_NODE);

static int16_t ring[RING_SAMPLES];
static size_t ring_head; /* next write index */
static uint32_t total_samples;
static struct k_spinlock lock;

static struct mic_stats stats;
static int pick = CONFIG_APP_MIC_PICK; /* -1 = auto */

K_THREAD_STACK_DEFINE(mic_stack, 3072);
static struct k_thread mic_thread;


#ifdef CONFIG_APP_MIC_DEBUG
#include <hal/gpio_ll.h>
#include <soc/gpio_struct.h>
/* Sample a pad's input buffer n times as fast as the CPU can; returns how many
 * reads were high. A live PDM data line or clock sits near 50 %. */
static unsigned pad_ones(int gpio, unsigned n)
{
	gpio_ll_input_enable(&GPIO, gpio);
	unsigned ones = 0;
	for (unsigned i = 0; i < n; i++) {
		ones += gpio_ll_get_level(&GPIO, gpio);
	}
	return ones;
}

/* Rising edges per second on a pad, from a tight polling loop timed with the
 * cycle counter. Fine for telling 32 kHz from 1 MHz; not a frequency counter. */
static unsigned pad_hz(int gpio, unsigned n)
{
	gpio_ll_input_enable(&GPIO, gpio);
	unsigned edges = 0, prev = gpio_ll_get_level(&GPIO, gpio);
	uint32_t t0 = k_cycle_get_32();
	for (unsigned i = 0; i < n; i++) {
		unsigned v = gpio_ll_get_level(&GPIO, gpio);
		edges += (v & ~prev) & 1u;
		prev = v;
	}
	uint32_t ns = k_cyc_to_ns_floor32(k_cycle_get_32() - t0);
	return ns ? (unsigned)((uint64_t)edges * 1000000000ull / ns) : 0;
}
#endif

static void push_samples(const int16_t *s, size_t n)
{
	k_spinlock_key_t key = k_spin_lock(&lock);
	for (size_t i = 0; i < n; i++) {
		ring[ring_head] = s[i];
		ring_head = (ring_head + 1) % RING_SAMPLES;
	}
	total_samples += n;
	k_spin_unlock(&lock, key);
}

static float rms_of(const int16_t *s, size_t n, size_t stride)
{
	double acc = 0.0;
	size_t cnt = 0;
	for (size_t i = 0; i < n; i += stride) {
		acc += (double)s[i] * (double)s[i];
		cnt++;
	}
	return cnt ? (float)sqrt(acc / (double)cnt) : 0.0f;
}

static void mic_thread_fn(void *a, void *b, void *c)
{
	static int16_t tmp[BLOCK_WORDS * 2];
	int64_t t0 = k_uptime_get();
	uint32_t words = 0, picked = 0;
	int64_t last_rate = t0;

	for (;;) {
		void *block;
		size_t size;
		int ret = i2s_read(i2s, &block, &size);
		if (ret != 0) {
			/* An RX overrun parks the Zephyr I2S stream in its error state and
			 * every read fails from then on: drop the queue and start again. */
			stats.overruns++;
			i2s_trigger(i2s, I2S_DIR_RX, I2S_TRIGGER_DROP);
			k_msleep(2);
			if (i2s_trigger(i2s, I2S_DIR_RX, I2S_TRIGGER_START) != 0) {
				k_msleep(20);
			}
			continue;
		}
		const int16_t *h = block;
		size_t nwords = size / 4;
		words += nwords;

		stats.rms_lo = rms_of(h, nwords * 2, 2);
		stats.rms_hi = rms_of(h + 1, nwords * 2 - 1, 2);

		int64_t now = k_uptime_get();
		if (pick < 0 && now - t0 >= 500) {
			/* ~16000 words/s: each word is one 16 kHz frame, take the louder half.
			 * ~8000 words/s: two mono samples per word, take every halfword. */
			uint32_t wps = (uint32_t)(words * 1000 / (uint32_t)(now - t0));
			if (wps < 12000) {
				pick = 2;
			} else {
				pick = stats.rms_hi > stats.rms_lo * 1.5f ? 1 : 0;
			}
			printk("mic: %u DMA words/s in the first %lld ms -> pick mode %d\n", wps,
			       (long long)(now - t0), pick);
		}
		if (pick >= 0) {
			size_t n = 0;
			if (pick == 2) {
				memcpy(tmp, h, nwords * 4);
				n = nwords * 2;
			} else {
				for (size_t i = 0; i < nwords; i++) {
					tmp[i] = h[2 * i + pick];
				}
				n = nwords;
			}
			push_samples(tmp, n);
			picked += n;
		}
		k_mem_slab_free(&mic_slab, block);

		if (now - last_rate >= 1000) {
			stats.words_per_s = (uint32_t)(words * 1000 / (uint32_t)(now - last_rate));
			stats.samples_per_s = (uint32_t)(picked * 1000 / (uint32_t)(now - last_rate));
			stats.pick = pick;
			words = 0;
			picked = 0;
			last_rate = now;
		}
	}
}

int mic_init(void)
{
	if (!device_is_ready(i2s)) {
		printk("mic: i2s0 not ready\n");
		return -ENODEV;
	}

	struct i2s_config cfg = {
		.word_size = 16,
		.channels = 2,
		.format = I2S_FMT_DATA_FORMAT_I2S,
		.options = I2S_OPT_FRAME_CLK_MASTER | I2S_OPT_BIT_CLK_MASTER,
		.frame_clk_freq = FRAME_HZ,
		.mem_slab = &mic_slab,
		.block_size = BLOCK_BYTES,
		.timeout = 1000,
	};
#ifdef CONFIG_APP_MIC_DEBUG
	printk("mic: pad levels before start: GPIO33 %u/2000 high, GPIO23 %u/2000 high\n", pad_ones(33, 2000),
	       pad_ones(23, 2000));
#endif
	int ret = i2s_configure(i2s, I2S_DIR_RX, &cfg);
	if (ret != 0) {
		printk("mic: i2s_configure failed (%d)\n", ret);
		return ret;
	}

	/* Standard mode is configured; now make the receiver a PDM-to-PCM one.
	 * Mirrors i2s_hal_pdm_set_rx_slot() / i2s_hal_pdm_enable_rx_channel()
	 * in ESP-IDF for the ESP32. */
	i2s_dev_t *hw = &I2S0;
	i2s_ll_rx_set_sample_bit(hw, 16, 16);
#if defined(CONFIG_APP_MIC_SLOT_BOTH)
	i2s_ll_rx_enable_mono_mode(hw, false);
	i2s_ll_rx_select_pdm_slot(hw, I2S_PDM_SLOT_BOTH);
#elif defined(CONFIG_APP_MIC_SLOT_LEFT)
	i2s_ll_rx_enable_mono_mode(hw, true);
	i2s_ll_rx_select_pdm_slot(hw, I2S_PDM_SLOT_LEFT);
#else
	i2s_ll_rx_enable_mono_mode(hw, true);
	i2s_ll_rx_select_pdm_slot(hw, I2S_PDM_SLOT_RIGHT);
#endif
	i2s_ll_rx_force_enable_fifo_mod(hw, true);
	i2s_ll_rx_enable_msb_right(hw, false);
	i2s_ll_rx_enable_right_first(hw, false);
	i2s_ll_rx_enable_msb_shift(hw, false);
	i2s_ll_rx_set_pdm_dsr(hw, I2S_PDM_DSR_8S);
	i2s_ll_rx_enable_pdm(hw, true);

	ret = i2s_trigger(i2s, I2S_DIR_RX, I2S_TRIGGER_START);
	if (ret != 0) {
		printk("mic: i2s start failed (%d)\n", ret);
		return ret;
	}

#ifdef CONFIG_APP_MIC_DEBUG
	k_msleep(5);
	printk("mic: pad levels after start: GPIO33 (clk) %u/2000 high, GPIO23 (data) %u/2000 high\n",
	       pad_ones(33, 2000), pad_ones(23, 2000));
	printk("mic: pad edge rates: GPIO33 (clk) ~%u Hz, GPIO23 (data) ~%u Hz\n", pad_hz(33, 400000),
	       pad_hz(23, 400000));
	printk("mic: regs pdm_conf=0x%08x conf=0x%08x conf_chan=0x%08x sample_rate=0x%08x clkm=0x%08x fifo_conf=0x%08x\n",
	       (unsigned)hw->pdm_conf.val, (unsigned)hw->conf.val, (unsigned)hw->conf_chan.val,
	       (unsigned)hw->sample_rate_conf.val, (unsigned)hw->clkm_conf.val, (unsigned)hw->fifo_conf.val);
#endif
	k_thread_create(&mic_thread, mic_stack, K_THREAD_STACK_SIZEOF(mic_stack), mic_thread_fn, NULL,
			NULL, NULL, K_PRIO_COOP(4), 0, K_NO_WAIT);
	k_thread_name_set(&mic_thread, "mic");
	printk("mic: SPM1423 PDM on I2S0 (clk GPIO33, data GPIO23), bck %u Hz, slot %s, pick %s\n",
	       FRAME_HZ * 32,
	       IS_ENABLED(CONFIG_APP_MIC_SLOT_BOTH) ? "both" : IS_ENABLED(CONFIG_APP_MIC_SLOT_LEFT) ? "left" : "right",
	       pick < 0 ? "auto" : "fixed");
	return 0;
}

size_t mic_read_latest(int16_t *out, size_t n)
{
	if (n > RING_SAMPLES) {
		n = RING_SAMPLES;
	}
	k_spinlock_key_t key = k_spin_lock(&lock);
	size_t avail = total_samples < RING_SAMPLES ? (size_t)total_samples : RING_SAMPLES;
	if (n > avail) {
		n = avail;
	}
	size_t start = (ring_head + RING_SAMPLES - n) % RING_SAMPLES;
	for (size_t i = 0; i < n; i++) {
		out[i] = ring[(start + i) % RING_SAMPLES];
	}
	k_spin_unlock(&lock, key);
	return n;
}

uint32_t mic_sample_count(void)
{
	k_spinlock_key_t key = k_spin_lock(&lock);
	uint32_t n = total_samples;
	k_spin_unlock(&lock, key);
	return n;
}

void mic_get_stats(struct mic_stats *out)
{
	*out = stats;
	out->pick = pick;
}
```

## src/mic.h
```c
/* Copyright (c) 2026 Eoin Jordan
 * SPDX-License-Identifier: Apache-2.0
 *
 * The ATOM Echo's SPM1423 PDM microphone through the ESP32's I2S0 PDM-to-PCM
 * path: 16 kHz, 16-bit mono into a ring buffer that the keyword spotter reads
 * one-second windows from.
 */
#pragma once

#include <stddef.h>
#include <stdint.h>

#ifdef __cplusplus
extern "C" {
#endif

struct mic_stats {
	uint32_t words_per_s;   /* 32-bit DMA words per second, measured */
	uint32_t samples_per_s; /* picked samples per second, measured */
	uint32_t overruns;
	int pick;               /* 0 low halfword, 1 high halfword, 2 every halfword */
	float rms_lo, rms_hi;   /* RMS of each halfword stream, last block */
};

int mic_init(void);

/* Copy the newest n samples (oldest first). Returns the number copied. */
size_t mic_read_latest(int16_t *out, size_t n);

/* Total samples captured so far (for "has a new hop arrived" checks). */
uint32_t mic_sample_count(void);

void mic_get_stats(struct mic_stats *out);

#ifdef __cplusplus
}
#endif
```
